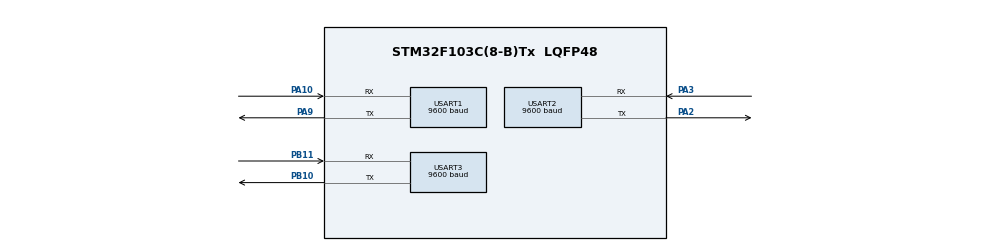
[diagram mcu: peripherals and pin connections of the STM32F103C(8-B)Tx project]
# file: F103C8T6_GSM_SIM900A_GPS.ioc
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Mcu.Family=STM32F1
Mcu.Name=STM32F103C(8-B)Tx
Mcu.Package=LQFP48
NVIC.PriorityGroup=NVIC_PRIORITYGROUP_4
NVIC.USART2_IRQn=true\:0\:0\:false\:false\:true\:true\:true\:true
PA10.Mode=Asynchronous
PA10.Signal=USART1_RX
PA13.Mode=Serial_Wire
PA13.Signal=SYS_JTMS-SWDIO
PA14.Mode=Serial_Wire
PA14.Signal=SYS_JTCK-SWCLK
PA2.Mode=Asynchronous
PA2.Signal=USART2_TX
PA3.Mode=Asynchronous
PA3.Signal=USART2_RX
PA9.Mode=Asynchronous
PA9.Signal=USART1_TX
PB10.Mode=Asynchronous
PB10.Signal=USART3_TX
PB11.Mode=Asynchronous
PB11.Signal=USART3_RX
PD0-OSC_IN.Mode=HSE-External-Oscillator
PD0-OSC_IN.Signal=RCC_OSC_IN
PD1-OSC_OUT.Mode=HSE-External-Oscillator
PD1-OSC_OUT.Signal=RCC_OSC_OUT
ProjectManager.HeapSize=0x200
ProjectManager.StackSize=0x400
ProjectManager.TargetToolchain=STM32CubeIDE
RCC.APB1Freq_Value=8000000
RCC.APB2Freq_Value=8000000
USART1.BaudRate=9600
USART1.VirtualMode=VM_ASYNC
USART2.BaudRate=9600
USART2.VirtualMode=VM_ASYNC
USART3.BaudRate=9600
USART3.VirtualMode=VM_ASYNC
board=custom

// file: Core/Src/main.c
/* USER CODE BEGIN Header */
/**
 ******************************************************************************
 * @file           : main.c
 * @brief          : Main program body
 ******************************************************************************
 * @attention
 *
 * Copyright (c) 2025 STMicroelectronics.
 * All rights reserved.
 *
 * This software is licensed under terms that can be found in the LICENSE file
 * in the root directory of this software component.
 * If no LICENSE file comes with this software, it is provided AS-IS.
 *
 ******************************************************************************
 */
/* USER CODE END Header */
#include "main.h"
#include "string.h"
#include "stdio.h"
#include "stdlib.h"

UART_HandleTypeDef huart1;
UART_HandleTypeDef huart2;
UART_HandleTypeDef huart3;

/* USER CODE BEGIN PV */
char gps_buffer[128];
char latest_lat[20] = "";
char latest_lon[20] = "";
char sms_buffer[160];
volatile uint8_t gps_ready = 0;
uint8_t rx_data_gps;
uint8_t rx_index = 0;

uint8_t command;
volatile uint8_t send_sms_flag = 0;
/* USER CODE END PV */

void SystemClock_Config(void);
static void MX_GPIO_Init(void);
static void MX_USART1_UART_Init(void);
static void MX_USART2_UART_Init(void);
static void MX_USART3_UART_Init(void);
void parse_GNGLL(const char *sentence);
void send_sms(const char *lat, const char *lon);
/* USER CODE END PFP */

int main(void) {

	/* MCU Configuration--------------------------------------------------------*/

	/* Reset of all peripherals, Initializes the Flash interface and the Systick. */
	HAL_Init();

	/* Configure the system clock */
	SystemClock_Config();

	/* Initialize all configured peripherals */
	MX_GPIO_Init();
	MX_USART1_UART_Init();
	MX_USART2_UART_Init();
	MX_USART3_UART_Init();
	/* USER CODE BEGIN 2 */
	HAL_UART_Transmit(&huart1, (uint8_t*) "System Ready\r\n", 14,
	HAL_MAX_DELAY);
	HAL_UART_Receive_IT(&huart2, &rx_data_gps, 1);  // GPS
	HAL_UART_Receive_IT(&huart1, &command, 1);      // PC Terminal
	// TeraTerm command

	/* USER CODE END 2 */

	/* Infinite loop */
	while (1) {
		if (gps_ready) {
			gps_ready = 0;

			if (strncmp(gps_buffer, "$GNGLL", 6) == 0) {
				parse_GNGLL(gps_buffer);
			}
		}

		if (send_sms_flag) {
			send_sms_flag = 0;
			send_sms(latest_lat, latest_lon);
		}
	}
}

void parse_GNGLL(const char *sentence) {
	char buffer[128];
	strcpy(buffer, sentence);

	char *token;
	char *fields[10] = { 0 };
	int i = 0;

	token = strtok(buffer, ",");
	while (token && i < 10) {
		fields[i++] = token;
		token = strtok(NULL, ",");
	}

	if (i < 6 || !fields[1] || !fields[3])
		return;

	float raw_lat = atof(fields[1]);
	float raw_lon = atof(fields[3]);

	int lat_deg = (int) (raw_lat / 100);
	float lat_min = raw_lat - (lat_deg * 100);
	float lat_decimal = lat_deg + (lat_min / 60.0f);

	int lon_deg = (int) (raw_lon / 100);
	float lon_min = raw_lon - (lon_deg * 100);
	float lon_decimal = lon_deg + (lon_min / 60.0f);

	snprintf(latest_lat, sizeof(latest_lat), "%.5f %s", lat_decimal, fields[2]);
	snprintf(latest_lon, sizeof(latest_lon), "%.5f %s", lon_decimal, fields[4]);

	char log_msg[128];
	snprintf(log_msg, sizeof(log_msg),
			"Parsed GPS:\r\nLatitude: %s\r\nLongitude: %s\r\n\r\n", latest_lat,
			latest_lon);
	HAL_UART_Transmit(&huart1, (uint8_t*) log_msg, strlen(log_msg),
	HAL_MAX_DELAY);
}

void HAL_UART_RxCpltCallback(UART_HandleTypeDef *huart) {
	// GPS data receive
	if (huart->Instance == USART2) {
		if (rx_index < sizeof(gps_buffer) - 1) {
			if (rx_data_gps == '\n') {
				gps_buffer[rx_index] = '\0';
				gps_ready = 1;
				rx_index = 0;
			} else {
				gps_buffer[rx_index++] = rx_data_gps;
			}
		}
		HAL_UART_Receive_IT(&huart2, &rx_data_gps, 1);
	}

	// PC Terminal command receive
	if (huart->Instance == USART1) {
		if (command == 's' || command == 'S') {
			send_sms_flag = 1;
		}
		HAL_UART_Receive_IT(&huart1, &command, 1);
	}
}

void send_sms(const char *lat, const char *lon) {
	const char *number = "+919985798499";  // Replace with your number
	char lat_buf[30], lon_buf[30];

	// If no GPS data available, fill with defaults
	if (strlen(lat) == 0)
		strcpy(lat_buf, "Not Available");
	else
		strcpy(lat_buf, lat);

	if (strlen(lon) == 0)
		strcpy(lon_buf, "Not Available");
	else
		strcpy(lon_buf, lon);

	sprintf(sms_buffer, "AT\r\n");
	HAL_UART_Transmit(&huart3, (uint8_t*) sms_buffer, strlen(sms_buffer),
			HAL_MAX_DELAY);
	HAL_Delay(1000);

	sprintf(sms_buffer, "AT+CMGF=1\r\n");  // Text mode
	HAL_UART_Transmit(&huart3, (uint8_t*) sms_buffer, strlen(sms_buffer),
			HAL_MAX_DELAY);
	HAL_Delay(1000);

	sprintf(sms_buffer, "AT+CMGS=\"%s\"\r\n", number);
	HAL_UART_Transmit(&huart3, (uint8_t*) sms_buffer, strlen(sms_buffer),
			HAL_MAX_DELAY);
	HAL_Delay(1000);

	sprintf(sms_buffer, "GPS Location:\r\nLatitude: %s\r\nLongitude: %s\r\n",
			lat_buf, lon_buf);
	HAL_UART_Transmit(&huart3, (uint8_t*) sms_buffer, strlen(sms_buffer),
			HAL_MAX_DELAY);
	HAL_Delay(1000);

	uint8_t ctrl_z = 0x1A;  // CTRL+Z
	HAL_UART_Transmit(&huart3, &ctrl_z, 1, HAL_MAX_DELAY);

	HAL_UART_Transmit(&huart1, (uint8_t*) "SMS Sent!\r\n", 11, HAL_MAX_DELAY);
}

void SystemClock_Config(void) {
	RCC_OscInitTypeDef RCC_OscInitStruct = { 0 };
	RCC_ClkInitTypeDef RCC_ClkInitStruct = { 0 };

	/** Initializes the RCC Oscillators according to the specified parameters
	 * in the RCC_OscInitTypeDef structure.
	 */
	RCC_OscInitStruct.OscillatorType = RCC_OSCILLATORTYPE_HSI;
	RCC_OscInitStruct.HSIState = RCC_HSI_ON;
	RCC_OscInitStruct.HSICalibrationValue = RCC_HSICALIBRATION_DEFAULT;
	RCC_OscInitStruct.PLL.PLLState = RCC_PLL_NONE;
	if (HAL_RCC_OscConfig(&RCC_OscInitStruct) != HAL_OK) {
		Error_Handler();
	}

	/** Initializes the CPU, AHB and APB buses clocks
	 */
	RCC_ClkInitStruct.ClockType = RCC_CLOCKTYPE_HCLK | RCC_CLOCKTYPE_SYSCLK
			| RCC_CLOCKTYPE_PCLK1 | RCC_CLOCKTYPE_PCLK2;
	RCC_ClkInitStruct.SYSCLKSource = RCC_SYSCLKSOURCE_HSI;
	RCC_ClkInitStruct.AHBCLKDivider = RCC_SYSCLK_DIV1;
	RCC_ClkInitStruct.APB1CLKDivider = RCC_HCLK_DIV1;
	RCC_ClkInitStruct.APB2CLKDivider = RCC_HCLK_DIV1;

	if (HAL_RCC_ClockConfig(&RCC_ClkInitStruct, FLASH_LATENCY_0) != HAL_OK) {
		Error_Handler();
	}
}

static void MX_USART1_UART_Init(void) {

	huart1.Instance = USART1;
	huart1.Init.BaudRate = 9600;
	huart1.Init.WordLength = UART_WORDLENGTH_8B;
	huart1.Init.StopBits = UART_STOPBITS_1;
	huart1.Init.Parity = UART_PARITY_NONE;
	huart1.Init.Mode = UART_MODE_TX_RX;
	huart1.Init.HwFlowCtl = UART_HWCONTROL_NONE;
	huart1.Init.OverSampling = UART_OVERSAMPLING_16;
	if (HAL_UART_Init(&huart1) != HAL_OK) {
		Error_Handler();
	}

}

static void MX_USART2_UART_Init(void) {

	huart2.Instance = USART2;
	huart2.Init.BaudRate = 9600;
	huart2.Init.WordLength = UART_WORDLENGTH_8B;
	huart2.Init.StopBits = UART_STOPBITS_1;
	huart2.Init.Parity = UART_PARITY_NONE;
	huart2.Init.Mode = UART_MODE_TX_RX;
	huart2.Init.HwFlowCtl = UART_HWCONTROL_NONE;
	huart2.Init.OverSampling = UART_OVERSAMPLING_16;
	if (HAL_UART_Init(&huart2) != HAL_OK) {
		Error_Handler();
	}

}

static void MX_USART3_UART_Init(void) {

	huart3.Instance = USART3;
	huart3.Init.BaudRate = 9600;
	huart3.Init.WordLength = UART_WORDLENGTH_8B;
	huart3.Init.StopBits = UART_STOPBITS_1;
	huart3.Init.Parity = UART_PARITY_NONE;
	huart3.Init.Mode = UART_MODE_TX_RX;
	huart3.Init.HwFlowCtl = UART_HWCONTROL_NONE;
	huart3.Init.OverSampling = UART_OVERSAMPLING_16;
	if (HAL_UART_Init(&huart3) != HAL_OK) {
		Error_Handler();
	}

}

static void MX_GPIO_Init(void) {

	/* GPIO Ports Clock Enable */
	__HAL_RCC_GPIOD_CLK_ENABLE();
	__HAL_RCC_GPIOA_CLK_ENABLE();
	__HAL_RCC_GPIOB_CLK_ENABLE();

}

void Error_Handler(void) {
	__disable_irq();
	while (1) {
	}
}
